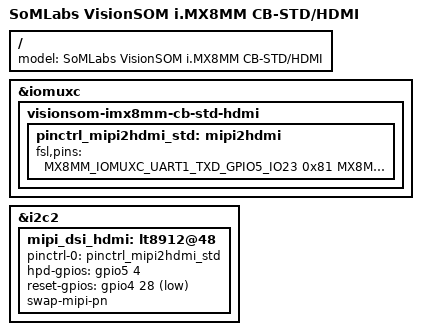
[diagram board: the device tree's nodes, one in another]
// SPDX-License-Identifier: GPL-2.0-or-later
/*
 * Copyright 2020 SomLabs
 *
 */

/dts-v1/;

#include "visionsom-8mm-cb.dtsi"
#include "visionsom-8mm-cb-hdmi.dtsi"

/ {
    model = "SoMLabs VisionSOM i.MX8MM CB-STD/HDMI";
};

&iomuxc {
    pinctrl-names = "default";

    visionsom-imx8mm-cb-std-hdmi {
        pinctrl_mipi2hdmi_std: mipi2hdmi {
            fsl,pins = <
                MX8MM_IOMUXC_UART1_TXD_GPIO5_IO23       0x81        /* interrupt */
                MX8MM_IOMUXC_SAI3_RXFS_GPIO4_IO28       0x19        /* reset */
                MX8MM_IOMUXC_SPDIF_RX_GPIO5_IO4         0x81        /* HPD */
            >;
        };
    };
};

&i2c2 {
    /* MIPI-DSI to HDMI adapter */
    mipi_dsi_hdmi: lt8912@48 {
        pinctrl-names = "default";
        pinctrl-0 = <&pinctrl_mipi2hdmi_std>;
        hpd-gpios = <&gpio5 4 GPIO_ACTIVE_HIGH>;
        reset-gpios = <&gpio4 28 GPIO_ACTIVE_LOW>;
        swap-mipi-pn;
    };
};
